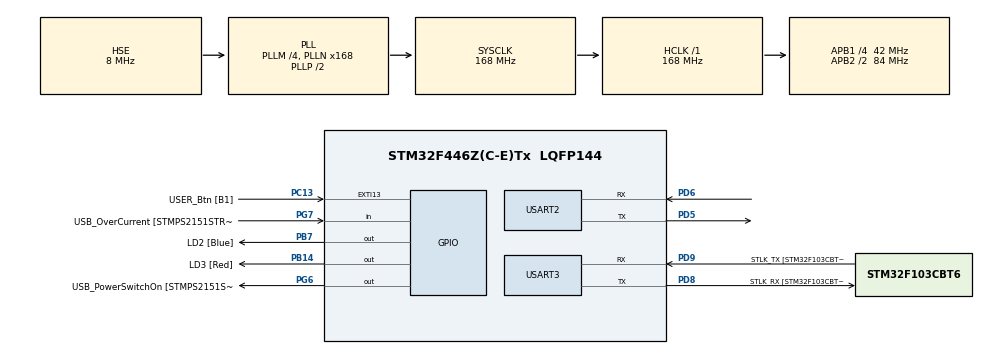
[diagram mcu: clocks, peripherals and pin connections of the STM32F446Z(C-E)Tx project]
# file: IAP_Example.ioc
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Mcu.Family=STM32F4
Mcu.Name=STM32F446Z(C-E)Tx
Mcu.Package=LQFP144
NVIC.PriorityGroup=NVIC_PRIORITYGROUP_4
PA10.GPIO_Label=USB_ID
PA10.Signal=USB_OTG_FS_ID
PA11.GPIO_Label=USB_DM
PA11.Signal=USB_OTG_FS_DM
PA12.GPIO_Label=USB_DP
PA12.Signal=USB_OTG_FS_DP
PA13.GPIO_Label=TMS
PA13.Mode=Serial_Wire
PA13.Signal=SYS_JTMS-SWDIO
PA14.GPIO_Label=TCK
PA14.Mode=Serial_Wire
PA14.Signal=SYS_JTCK-SWCLK
PA8.GPIO_Label=USB_SOF [TP1]
PA8.Signal=USB_OTG_FS_SOF
PA9.GPIO_Label=USB_VBUS
PA9.Signal=USB_OTG_FS_VBUS
PB14.GPIO_Label=LD3 [Red]
PB14.Signal=GPIO_Output
PB7.GPIO_Label=LD2 [Blue]
PB7.Signal=GPIO_Output
PC13.GPIO_Label=USER_Btn [B1]
PC13.Signal=GPXTI13
PC14-OSC32_IN.Mode=LSE-External-Oscillator
PC14-OSC32_IN.Signal=RCC_OSC32_IN
PC15-OSC32_OUT.Mode=LSE-External-Oscillator
PC15-OSC32_OUT.Signal=RCC_OSC32_OUT
PD5.Mode=Asynchronous
PD5.Signal=USART2_TX
PD6.Mode=Asynchronous
PD6.Signal=USART2_RX
PD8.GPIO_Label=STLK_RX [STM32F103CBT6_PA3]
PD8.Mode=Asynchronous
PD8.Signal=USART3_TX
PD9.GPIO_Label=STLK_TX [STM32F103CBT6_PA2]
PD9.Mode=Asynchronous
PD9.Signal=USART3_RX
PG6.GPIO_Label=USB_PowerSwitchOn [STMPS2151STR_EN]
PG6.Signal=GPIO_Output
PG7.GPIO_Label=USB_OverCurrent [STMPS2151STR_FAULT]
PG7.Signal=GPIO_Input
PH0-OSC_IN.GPIO_Label=MCO [STM32F103CBT6_PA8]
PH0-OSC_IN.Mode=HSE-External-Clock-Source
PH0-OSC_IN.Signal=RCC_OSC_IN
PH1-OSC_OUT.Mode=HSE-External-Clock-Source
PH1-OSC_OUT.Signal=RCC_OSC_OUT
ProjectManager.HeapSize=0x400
ProjectManager.StackSize=0x800
ProjectManager.TargetToolchain=Makefile
RCC.48MHZClocksFreq_Value=24000000
RCC.AHBFreq_Value=168000000
RCC.APB1CLKDivider=RCC_HCLK_DIV4
RCC.APB1Freq_Value=42000000
RCC.APB1TimFreq_Value=84000000
RCC.APB2CLKDivider=RCC_HCLK_DIV2
RCC.APB2Freq_Value=84000000
RCC.APB2TimFreq_Value=168000000
RCC.CortexFreq_Value=168000000
RCC.HCLKFreq_Value=168000000
RCC.HSE_VALUE=8000000
RCC.HSI_VALUE=16000000
RCC.PLLM=4
RCC.PLLMUL=RCC_PLL_MUL9
RCC.PLLN=168
RCC.PLLQ=7
RCC.PLLSourceVirtual=RCC_PLLSOURCE_HSE
RCC.PRESCALERUSB=RCC_USBCLKSOURCE_PLL_DIV1_5
RCC.SYSCLKFreq_VALUE=168000000
RCC.SYSCLKSource=RCC_SYSCLKSOURCE_PLLCLK
RCC.SYSCLKSourceVirtual=RCC_SYSCLKSOURCE_PLLCLK
RCC.USBFreq_Value=48000000
RCC.VCOOutputFreq_Value=336000000
USART2.VirtualMode=VM_ASYNC
USART3.VirtualMode=VM_ASYNC
board=NUCLEO-F446ZE

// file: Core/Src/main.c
/**
  ******************************************************************************
  * @file           : main.c
  * @brief          : Main program body
  ******************************************************************************
  ** This notice applies to any and all portions of this file
  * that are not between comment pairs USER CODE BEGIN and
  * USER CODE END. Other portions of this file, whether
  * inserted by the user or by software development tools
  * are owned by their respective copyright owners.
  *
  * COPYRIGHT(c) 2018 STMicroelectronics
  *
  * Redistribution and use in source and binary forms, with or without modification,
  * are permitted provided that the following conditions are met:
  *   1. Redistributions of source code must retain the above copyright notice,
  *      this list of conditions and the following disclaimer.
  *   2. Redistributions in binary form must reproduce the above copyright notice,
  *      this list of conditions and the following disclaimer in the documentation
  *      and/or other materials provided with the distribution.
  *   3. Neither the name of STMicroelectronics nor the names of its contributors
  *      may be used to endorse or promote products derived from this software
  *      without specific prior written permission.
  *
  * THIS SOFTWARE IS PROVIDED BY THE COPYRIGHT HOLDERS AND CONTRIBUTORS "AS IS"
  * AND ANY EXPRESS OR IMPLIED WARRANTIES, INCLUDING, BUT NOT LIMITED TO, THE
  * IMPLIED WARRANTIES OF MERCHANTABILITY AND FITNESS FOR A PARTICULAR PURPOSE ARE
  * DISCLAIMED. IN NO EVENT SHALL THE COPYRIGHT HOLDER OR CONTRIBUTORS BE LIABLE
  * FOR ANY DIRECT, INDIRECT, INCIDENTAL, SPECIAL, EXEMPLARY, OR CONSEQUENTIAL
  * DAMAGES (INCLUDING, BUT NOT LIMITED TO, PROCUREMENT OF SUBSTITUTE GOODS OR
  * SERVICES; LOSS OF USE, DATA, OR PROFITS; OR BUSINESS INTERRUPTION) HOWEVER
  * CAUSED AND ON ANY THEORY OF LIABILITY, WHETHER IN CONTRACT, STRICT LIABILITY,
  * OR TORT (INCLUDING NEGLIGENCE OR OTHERWISE) ARISING IN ANY WAY OUT OF THE USE
  * OF THIS SOFTWARE, EVEN IF ADVISED OF THE POSSIBILITY OF SUCH DAMAGE.
  *
  ******************************************************************************
  */
#include "main.h"
#include "stm32f4xx_hal.h"
#include "usart.h"
#include "gpio.h"

/* USER CODE BEGIN Includes */
#include "menu.h"

/* USER CODE END Includes */

/* USER CODE BEGIN PV */
/* Private variables ---------------------------------------------------------*/
extern pFunction JumpToApplication;
extern uint32_t JumpAddress;

/* USER CODE END PV */

void SystemClock_Config(void);

/* USER CODE BEGIN PFP */
/* Private function prototypes -----------------------------------------------*/

/* USER CODE END PFP */

int main(void)
{

  /* MCU Configuration----------------------------------------------------------*/

  /* Reset of all peripherals, Initializes the Flash interface and the Systick. */
  HAL_Init();

  /* Configure the system clock */
  SystemClock_Config();

  /* Initialize all configured peripherals */
  MX_GPIO_Init();
  MX_USART3_UART_Init();
  MX_USART2_UART_Init();
  /* USER CODE BEGIN 2 */

  if (HAL_GPIO_ReadPin(USER_Btn_GPIO_Port, USER_Btn_Pin) == GPIO_PIN_SET) {
    Main_Menu();
  }
  else {
    if (((*(__IO uint32_t*)APPLICATION_ADDRESS) & 0x2FFC0000) == 0x20000000) {
      /* Get User application Reset_Handler function pointer */
      JumpAddress = *(__IO uint32_t*) (APPLICATION_ADDRESS + 4);
      JumpToApplication = (pFunction) JumpAddress;
      /* Initialize user application's Stack Pointer */
      __set_MSP(*(__IO uint32_t*) APPLICATION_ADDRESS);
      JumpToApplication();
    }
  }

  /* USER CODE END 2 */

  /* Infinite loop */
  while (1)
  {

  }

}

void SystemClock_Config(void)
{

  RCC_OscInitTypeDef RCC_OscInitStruct;
  RCC_ClkInitTypeDef RCC_ClkInitStruct;

    /**Configure the main internal regulator output voltage
    */
  __HAL_RCC_PWR_CLK_ENABLE();

  __HAL_PWR_VOLTAGESCALING_CONFIG(PWR_REGULATOR_VOLTAGE_SCALE1);

    /**Initializes the CPU, AHB and APB busses clocks
    */
  RCC_OscInitStruct.OscillatorType = RCC_OSCILLATORTYPE_HSE;
  RCC_OscInitStruct.HSEState = RCC_HSE_BYPASS;
  RCC_OscInitStruct.PLL.PLLState = RCC_PLL_ON;
  RCC_OscInitStruct.PLL.PLLSource = RCC_PLLSOURCE_HSE;
  RCC_OscInitStruct.PLL.PLLM = 4;
  RCC_OscInitStruct.PLL.PLLN = 168;
  RCC_OscInitStruct.PLL.PLLP = RCC_PLLP_DIV2;
  RCC_OscInitStruct.PLL.PLLQ = 7;
  RCC_OscInitStruct.PLL.PLLR = 2;
  if (HAL_RCC_OscConfig(&RCC_OscInitStruct) != HAL_OK)
  {
    _Error_Handler(__FILE__, __LINE__);
  }

    /**Initializes the CPU, AHB and APB busses clocks
    */
  RCC_ClkInitStruct.ClockType = RCC_CLOCKTYPE_HCLK|RCC_CLOCKTYPE_SYSCLK
                              |RCC_CLOCKTYPE_PCLK1|RCC_CLOCKTYPE_PCLK2;
  RCC_ClkInitStruct.SYSCLKSource = RCC_SYSCLKSOURCE_PLLCLK;
  RCC_ClkInitStruct.AHBCLKDivider = RCC_SYSCLK_DIV1;
  RCC_ClkInitStruct.APB1CLKDivider = RCC_HCLK_DIV4;
  RCC_ClkInitStruct.APB2CLKDivider = RCC_HCLK_DIV2;

  if (HAL_RCC_ClockConfig(&RCC_ClkInitStruct, FLASH_LATENCY_5) != HAL_OK)
  {
    _Error_Handler(__FILE__, __LINE__);
  }

    /**Configure the Systick interrupt time
    */
  HAL_SYSTICK_Config(HAL_RCC_GetHCLKFreq()/1000);

    /**Configure the Systick
    */
  HAL_SYSTICK_CLKSourceConfig(SYSTICK_CLKSOURCE_HCLK);

  /* SysTick_IRQn interrupt configuration */
  HAL_NVIC_SetPriority(SysTick_IRQn, 0, 0);
}

void _Error_Handler(char *file, int line)
{
  while(1)
  {
  }
}

/************************ (C) COPYRIGHT STMicroelectronics *****END OF FILE****/
